# ECC_AGGR6_ECC_AGGR register map
Vendor: Texas Instruments
Registers are 32-bit, access not given, reset 0x0 unless marked. A register's access mark holds for its fields unless they carry their own. Offsets are as the file gives them; [hi:lo] are bit positions.

## ECC_AGGR6_ECC_AGGR (part 4 of 4)
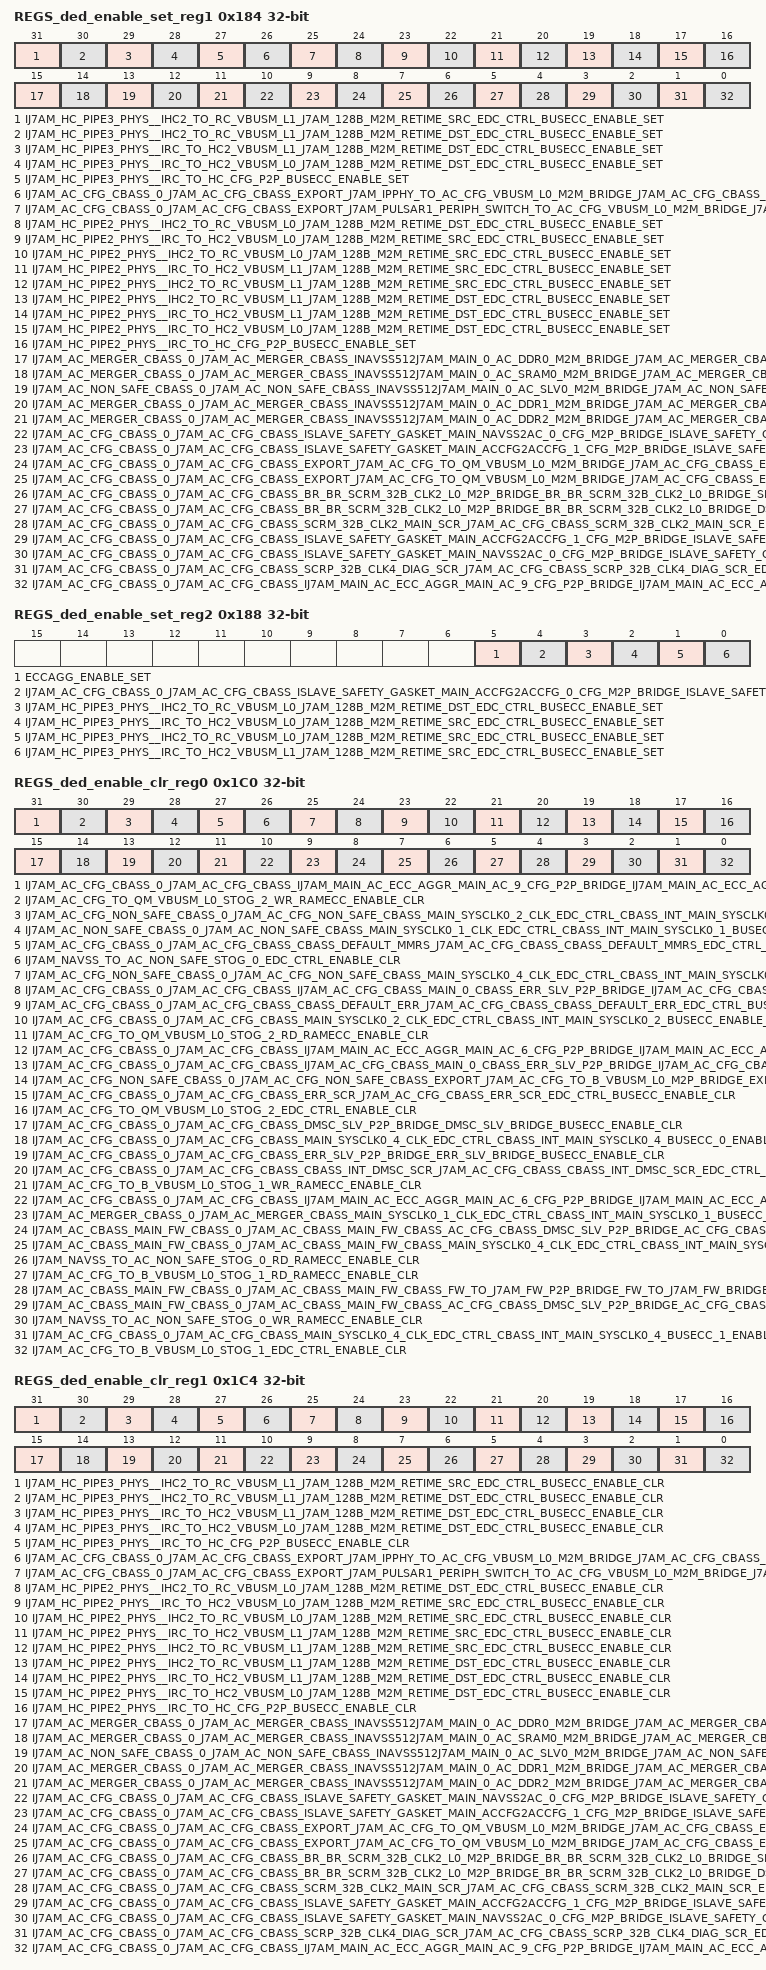
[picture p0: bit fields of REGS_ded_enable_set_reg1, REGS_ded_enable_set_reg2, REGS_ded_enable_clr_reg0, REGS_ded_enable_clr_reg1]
0x184 REGS_ded_enable_set_reg1 — Interrupt Enable Set Register 1
  [31] IJ7AM_HC_PIPE3_PHYS__IHC2_TO_RC_VBUSM_L1_J7AM_128B_M2M_RETIME_SRC_EDC_CTRL_BUSECC_ENABLE_SET — Interrupt Enable Set Register for Ij7am_hc_pipe3_phys__Ihc2_to_rc_vbusm_l1_j7am_128b_m2m_retime_src_edc_ctrl_busecc_pend (access R/W1TS)
  [30] IJ7AM_HC_PIPE3_PHYS__IHC2_TO_RC_VBUSM_L1_J7AM_128B_M2M_RETIME_DST_EDC_CTRL_BUSECC_ENABLE_SET — Interrupt Enable Set Register for Ij7am_hc_pipe3_phys__Ihc2_to_rc_vbusm_l1_j7am_128b_m2m_retime_dst_edc_ctrl_busecc_pend (access R/W1TS)
  [29] IJ7AM_HC_PIPE3_PHYS__IRC_TO_HC2_VBUSM_L1_J7AM_128B_M2M_RETIME_DST_EDC_CTRL_BUSECC_ENABLE_SET — Interrupt Enable Set Register for Ij7am_hc_pipe3_phys__Irc_to_hc2_vbusm_l1_j7am_128b_m2m_retime_dst_edc_ctrl_busecc_pend (access R/W1TS)
  [28] IJ7AM_HC_PIPE3_PHYS__IRC_TO_HC2_VBUSM_L0_J7AM_128B_M2M_RETIME_DST_EDC_CTRL_BUSECC_ENABLE_SET — Interrupt Enable Set Register for Ij7am_hc_pipe3_phys__Irc_to_hc2_vbusm_l0_j7am_128b_m2m_retime_dst_edc_ctrl_busecc_pend (access R/W1TS)
  [27] IJ7AM_HC_PIPE3_PHYS__IRC_TO_HC_CFG_P2P_BUSECC_ENABLE_SET — Interrupt Enable Set Register for Ij7am_hc_pipe3_phys__Irc_to_hc_cfg_p2p_busecc_pend (access R/W1TS)
  [26] IJ7AM_AC_CFG_CBASS_0_J7AM_AC_CFG_CBASS_EXPORT_J7AM_IPPHY_TO_AC_CFG_VBUSM_L0_M2M_BRIDGE_J7AM_AC_CFG_CBASS_EXPORT_J7AM_IPPHY_TO_AC_CFG_VBUSM_L0_M2M_BRIDGE_SRC_EDC_CTRL_BUSECC_ENABLE_SET — Interrupt Enable Set Register for Ij7am_ac_cfg_cbass_0_j7am_ac_cfg_cbass_export_j7am_ipphy_to_ac_cfg_vbusm_l0_m2m_bridge_j7am_ac_cfg_cbass_export_j7am_ipphy_to_ac_cfg_vbusm_l0_m2m_bridge_src_edc_ctrl_busecc_pend (access R/W1TS)
  [25] IJ7AM_AC_CFG_CBASS_0_J7AM_AC_CFG_CBASS_EXPORT_J7AM_PULSAR1_PERIPH_SWITCH_TO_AC_CFG_VBUSM_L0_M2M_BRIDGE_J7AM_AC_CFG_CBASS_EXPORT_J7AM_PULSAR1_PERIPH_SWITCH_TO_AC_CFG_VBUSM_L0_M2M_BRIDGE_SRC_EDC_CTRL_BUSECC_ENABLE_SET — Interrupt Enable Set Register for Ij7am_ac_cfg_cbass_0_j7am_ac_cfg_cbass_export_j7am_pulsar1_periph_switch_to_ac_cfg_vbusm_l0_m2m_bridge_j7am_ac_cfg_cbass_export_j7am_pulsar1_periph_switch_to_ac_cfg_vbusm_l0_m2m_bridge_src_edc_ctrl_busecc_pend (access R/W1TS)
  [24] IJ7AM_HC_PIPE2_PHYS__IHC2_TO_RC_VBUSM_L0_J7AM_128B_M2M_RETIME_DST_EDC_CTRL_BUSECC_ENABLE_SET — Interrupt Enable Set Register for Ij7am_hc_pipe2_phys__Ihc2_to_rc_vbusm_l0_j7am_128b_m2m_retime_dst_edc_ctrl_busecc_pend (access R/W1TS)
  [23] IJ7AM_HC_PIPE2_PHYS__IRC_TO_HC2_VBUSM_L0_J7AM_128B_M2M_RETIME_SRC_EDC_CTRL_BUSECC_ENABLE_SET — Interrupt Enable Set Register for Ij7am_hc_pipe2_phys__Irc_to_hc2_vbusm_l0_j7am_128b_m2m_retime_src_edc_ctrl_busecc_pend (access R/W1TS)
  [22] IJ7AM_HC_PIPE2_PHYS__IHC2_TO_RC_VBUSM_L0_J7AM_128B_M2M_RETIME_SRC_EDC_CTRL_BUSECC_ENABLE_SET — Interrupt Enable Set Register for Ij7am_hc_pipe2_phys__Ihc2_to_rc_vbusm_l0_j7am_128b_m2m_retime_src_edc_ctrl_busecc_pend (access R/W1TS)
  [21] IJ7AM_HC_PIPE2_PHYS__IRC_TO_HC2_VBUSM_L1_J7AM_128B_M2M_RETIME_SRC_EDC_CTRL_BUSECC_ENABLE_SET — Interrupt Enable Set Register for Ij7am_hc_pipe2_phys__Irc_to_hc2_vbusm_l1_j7am_128b_m2m_retime_src_edc_ctrl_busecc_pend (access R/W1TS)
  [20] IJ7AM_HC_PIPE2_PHYS__IHC2_TO_RC_VBUSM_L1_J7AM_128B_M2M_RETIME_SRC_EDC_CTRL_BUSECC_ENABLE_SET — Interrupt Enable Set Register for Ij7am_hc_pipe2_phys__Ihc2_to_rc_vbusm_l1_j7am_128b_m2m_retime_src_edc_ctrl_busecc_pend (access R/W1TS)
  [19] IJ7AM_HC_PIPE2_PHYS__IHC2_TO_RC_VBUSM_L1_J7AM_128B_M2M_RETIME_DST_EDC_CTRL_BUSECC_ENABLE_SET — Interrupt Enable Set Register for Ij7am_hc_pipe2_phys__Ihc2_to_rc_vbusm_l1_j7am_128b_m2m_retime_dst_edc_ctrl_busecc_pend (access R/W1TS)
  [18] IJ7AM_HC_PIPE2_PHYS__IRC_TO_HC2_VBUSM_L1_J7AM_128B_M2M_RETIME_DST_EDC_CTRL_BUSECC_ENABLE_SET — Interrupt Enable Set Register for Ij7am_hc_pipe2_phys__Irc_to_hc2_vbusm_l1_j7am_128b_m2m_retime_dst_edc_ctrl_busecc_pend (access R/W1TS)
  [17] IJ7AM_HC_PIPE2_PHYS__IRC_TO_HC2_VBUSM_L0_J7AM_128B_M2M_RETIME_DST_EDC_CTRL_BUSECC_ENABLE_SET — Interrupt Enable Set Register for Ij7am_hc_pipe2_phys__Irc_to_hc2_vbusm_l0_j7am_128b_m2m_retime_dst_edc_ctrl_busecc_pend (access R/W1TS)
  [16] IJ7AM_HC_PIPE2_PHYS__IRC_TO_HC_CFG_P2P_BUSECC_ENABLE_SET — Interrupt Enable Set Register for Ij7am_hc_pipe2_phys__Irc_to_hc_cfg_p2p_busecc_pend (access R/W1TS)
  [15] IJ7AM_AC_MERGER_CBASS_0_J7AM_AC_MERGER_CBASS_INAVSS512J7AM_MAIN_0_AC_DDR0_M2M_BRIDGE_J7AM_AC_MERGER_CBASS_INAVSS512J7AM_MAIN_0_AC_DDR0_M2M_BRIDGE_SRC_EDC_CTRL_BUSECC_ENABLE_SET — Interrupt Enable Set Register for Ij7am_ac_merger_cbass_0_j7am_ac_merger_cbass_Inavss512j7am_main_0_ac_ddr0_m2m_bridge_j7am_ac_merger_cbass_Inavss512j7am_main_0_ac_ddr0_m2m_bridge_src_edc_ctrl_busecc_pend (access R/W1TS)
  [14] IJ7AM_AC_MERGER_CBASS_0_J7AM_AC_MERGER_CBASS_INAVSS512J7AM_MAIN_0_AC_SRAM0_M2M_BRIDGE_J7AM_AC_MERGER_CBASS_INAVSS512J7AM_MAIN_0_AC_SRAM0_M2M_BRIDGE_SRC_EDC_CTRL_BUSECC_ENABLE_SET — Interrupt Enable Set Register for Ij7am_ac_merger_cbass_0_j7am_ac_merger_cbass_Inavss512j7am_main_0_ac_sram0_m2m_bridge_j7am_ac_merger_cbass_Inavss512j7am_main_0_ac_sram0_m2m_bridge_src_edc_ctrl_busecc_pend (access R/W1TS)
  [13] IJ7AM_AC_NON_SAFE_CBASS_0_J7AM_AC_NON_SAFE_CBASS_INAVSS512J7AM_MAIN_0_AC_SLV0_M2M_BRIDGE_J7AM_AC_NON_SAFE_CBASS_INAVSS512J7AM_MAIN_0_AC_SLV0_M2M_BRIDGE_SRC_EDC_CTRL_BUSECC_ENABLE_SET — Interrupt Enable Set Register for Ij7am_ac_non_safe_cbass_0_j7am_ac_non_safe_cbass_Inavss512j7am_main_0_ac_slv0_m2m_bridge_j7am_ac_non_safe_cbass_Inavss512j7am_main_0_ac_slv0_m2m_bridge_src_edc_ctrl_busecc_pend (access R/W1TS)
  [12] IJ7AM_AC_MERGER_CBASS_0_J7AM_AC_MERGER_CBASS_INAVSS512J7AM_MAIN_0_AC_DDR1_M2M_BRIDGE_J7AM_AC_MERGER_CBASS_INAVSS512J7AM_MAIN_0_AC_DDR1_M2M_BRIDGE_SRC_EDC_CTRL_BUSECC_ENABLE_SET — Interrupt Enable Set Register for Ij7am_ac_merger_cbass_0_j7am_ac_merger_cbass_Inavss512j7am_main_0_ac_ddr1_m2m_bridge_j7am_ac_merger_cbass_Inavss512j7am_main_0_ac_ddr1_m2m_bridge_src_edc_ctrl_busecc_pend (access R/W1TS)
  [11] IJ7AM_AC_MERGER_CBASS_0_J7AM_AC_MERGER_CBASS_INAVSS512J7AM_MAIN_0_AC_DDR2_M2M_BRIDGE_J7AM_AC_MERGER_CBASS_INAVSS512J7AM_MAIN_0_AC_DDR2_M2M_BRIDGE_SRC_EDC_CTRL_BUSECC_ENABLE_SET — Interrupt Enable Set Register for Ij7am_ac_merger_cbass_0_j7am_ac_merger_cbass_Inavss512j7am_main_0_ac_ddr2_m2m_bridge_j7am_ac_merger_cbass_Inavss512j7am_main_0_ac_ddr2_m2m_bridge_src_edc_ctrl_busecc_pend (access R/W1TS)
  [10] IJ7AM_AC_CFG_CBASS_0_J7AM_AC_CFG_CBASS_ISLAVE_SAFETY_GASKET_MAIN_NAVSS2AC_0_CFG_M2P_BRIDGE_ISLAVE_SAFETY_GASKET_MAIN_NAVSS2AC_0_CFG_BRIDGE_DST_BUSECC_ENABLE_SET — Interrupt Enable Set Register for Ij7am_ac_cfg_cbass_0_j7am_ac_cfg_cbass_Islave_safety_gasket_main_navss2ac_0_cfg_m2p_bridge_Islave_safety_gasket_main_navss2ac_0_cfg_bridge_dst_busecc_pend (access R/W1TS)
  [9] IJ7AM_AC_CFG_CBASS_0_J7AM_AC_CFG_CBASS_ISLAVE_SAFETY_GASKET_MAIN_ACCFG2ACCFG_1_CFG_M2P_BRIDGE_ISLAVE_SAFETY_GASKET_MAIN_ACCFG2ACCFG_1_CFG_BRIDGE_DST_BUSECC_ENABLE_SET — Interrupt Enable Set Register for Ij7am_ac_cfg_cbass_0_j7am_ac_cfg_cbass_Islave_safety_gasket_main_accfg2accfg_1_cfg_m2p_bridge_Islave_safety_gasket_main_accfg2accfg_1_cfg_bridge_dst_busecc_pend (access R/W1TS)
  [8] IJ7AM_AC_CFG_CBASS_0_J7AM_AC_CFG_CBASS_EXPORT_J7AM_AC_CFG_TO_QM_VBUSM_L0_M2M_BRIDGE_J7AM_AC_CFG_CBASS_EXPORT_J7AM_AC_CFG_TO_QM_VBUSM_L0_M2M_BRIDGE_DST_EDC_CTRL_BUSECC_ENABLE_SET — Interrupt Enable Set Register for Ij7am_ac_cfg_cbass_0_j7am_ac_cfg_cbass_export_j7am_ac_cfg_to_qm_vbusm_l0_m2m_bridge_j7am_ac_cfg_cbass_export_j7am_ac_cfg_to_qm_vbusm_l0_m2m_bridge_dst_edc_ctrl_busecc_pend (access R/W1TS)
  [7] IJ7AM_AC_CFG_CBASS_0_J7AM_AC_CFG_CBASS_EXPORT_J7AM_AC_CFG_TO_QM_VBUSM_L0_M2M_BRIDGE_J7AM_AC_CFG_CBASS_EXPORT_J7AM_AC_CFG_TO_QM_VBUSM_L0_M2M_BRIDGE_SRC_EDC_CTRL_BUSECC_ENABLE_SET — Interrupt Enable Set Register for Ij7am_ac_cfg_cbass_0_j7am_ac_cfg_cbass_export_j7am_ac_cfg_to_qm_vbusm_l0_m2m_bridge_j7am_ac_cfg_cbass_export_j7am_ac_cfg_to_qm_vbusm_l0_m2m_bridge_src_edc_ctrl_busecc_pend (access R/W1TS)
  [6] IJ7AM_AC_CFG_CBASS_0_J7AM_AC_CFG_CBASS_BR_BR_SCRM_32B_CLK2_L0_M2P_BRIDGE_BR_BR_SCRM_32B_CLK2_L0_BRIDGE_SRC_BUSECC_ENABLE_SET — Interrupt Enable Set Register for Ij7am_ac_cfg_cbass_0_j7am_ac_cfg_cbass_br_br_scrm_32b_clk2_l0_m2p_bridge_br_br_scrm_32b_clk2_l0_bridge_src_busecc_pend (access R/W1TS)
  [5] IJ7AM_AC_CFG_CBASS_0_J7AM_AC_CFG_CBASS_BR_BR_SCRM_32B_CLK2_L0_M2P_BRIDGE_BR_BR_SCRM_32B_CLK2_L0_BRIDGE_DST_BUSECC_ENABLE_SET — Interrupt Enable Set Register for Ij7am_ac_cfg_cbass_0_j7am_ac_cfg_cbass_br_br_scrm_32b_clk2_l0_m2p_bridge_br_br_scrm_32b_clk2_l0_bridge_dst_busecc_pend (access R/W1TS)
  [4] IJ7AM_AC_CFG_CBASS_0_J7AM_AC_CFG_CBASS_SCRM_32B_CLK2_MAIN_SCR_J7AM_AC_CFG_CBASS_SCRM_32B_CLK2_MAIN_SCR_EDC_CTRL_BUSECC_ENABLE_SET — Interrupt Enable Set Register for Ij7am_ac_cfg_cbass_0_j7am_ac_cfg_cbass_scrm_32b_clk2_main_scr_j7am_ac_cfg_cbass_scrm_32b_clk2_main_scr_edc_ctrl_busecc_pend (access R/W1TS)
  [3] IJ7AM_AC_CFG_CBASS_0_J7AM_AC_CFG_CBASS_ISLAVE_SAFETY_GASKET_MAIN_ACCFG2ACCFG_1_CFG_M2P_BRIDGE_ISLAVE_SAFETY_GASKET_MAIN_ACCFG2ACCFG_1_CFG_BRIDGE_SRC_BUSECC_ENABLE_SET — Interrupt Enable Set Register for Ij7am_ac_cfg_cbass_0_j7am_ac_cfg_cbass_Islave_safety_gasket_main_accfg2accfg_1_cfg_m2p_bridge_Islave_safety_gasket_main_accfg2accfg_1_cfg_bridge_src_busecc_pend (access R/W1TS)
  [2] IJ7AM_AC_CFG_CBASS_0_J7AM_AC_CFG_CBASS_ISLAVE_SAFETY_GASKET_MAIN_NAVSS2AC_0_CFG_M2P_BRIDGE_ISLAVE_SAFETY_GASKET_MAIN_NAVSS2AC_0_CFG_BRIDGE_SRC_BUSECC_ENABLE_SET — Interrupt Enable Set Register for Ij7am_ac_cfg_cbass_0_j7am_ac_cfg_cbass_Islave_safety_gasket_main_navss2ac_0_cfg_m2p_bridge_Islave_safety_gasket_main_navss2ac_0_cfg_bridge_src_busecc_pend (access R/W1TS)
  [1] IJ7AM_AC_CFG_CBASS_0_J7AM_AC_CFG_CBASS_SCRP_32B_CLK4_DIAG_SCR_J7AM_AC_CFG_CBASS_SCRP_32B_CLK4_DIAG_SCR_EDC_CTRL_BUSECC_ENABLE_SET — Interrupt Enable Set Register for Ij7am_ac_cfg_cbass_0_j7am_ac_cfg_cbass_scrp_32b_clk4_diag_scr_j7am_ac_cfg_cbass_scrp_32b_clk4_diag_scr_edc_ctrl_busecc_pend (access R/W1TS)
  [0] IJ7AM_AC_CFG_CBASS_0_J7AM_AC_CFG_CBASS_IJ7AM_MAIN_AC_ECC_AGGR_MAIN_AC_9_CFG_P2P_BRIDGE_IJ7AM_MAIN_AC_ECC_AGGR_MAIN_AC_9_CFG_BRIDGE_DST_BUSECC_ENABLE_SET — Interrupt Enable Set Register for Ij7am_ac_cfg_cbass_0_j7am_ac_cfg_cbass_Ij7am_main_ac_ecc_aggr_main_ac_9_cfg_p2p_bridge_Ij7am_main_ac_ecc_aggr_main_ac_9_cfg_bridge_dst_busecc_pend (access R/W1TS)
0x188 REGS_ded_enable_set_reg2 — Interrupt Enable Set Register 2
  [5] ECCAGG_ENABLE_SET — Interrupt Enable Set Register for eccagg_pend (access R/W1TS)
  [4] IJ7AM_AC_CFG_CBASS_0_J7AM_AC_CFG_CBASS_ISLAVE_SAFETY_GASKET_MAIN_ACCFG2ACCFG_0_CFG_M2P_BRIDGE_ISLAVE_SAFETY_GASKET_MAIN_ACCFG2ACCFG_0_CFG_BRIDGE_BUSECC_ENABLE_SET — Interrupt Enable Set Register for Ij7am_ac_cfg_cbass_0_j7am_ac_cfg_cbass_Islave_safety_gasket_main_accfg2accfg_0_cfg_m2p_bridge_Islave_safety_gasket_main_accfg2accfg_0_cfg_bridge_busecc_pend (access R/W1TS)
  [3] IJ7AM_HC_PIPE3_PHYS__IHC2_TO_RC_VBUSM_L0_J7AM_128B_M2M_RETIME_DST_EDC_CTRL_BUSECC_ENABLE_SET — Interrupt Enable Set Register for Ij7am_hc_pipe3_phys__Ihc2_to_rc_vbusm_l0_j7am_128b_m2m_retime_dst_edc_ctrl_busecc_pend (access R/W1TS)
  [2] IJ7AM_HC_PIPE3_PHYS__IRC_TO_HC2_VBUSM_L0_J7AM_128B_M2M_RETIME_SRC_EDC_CTRL_BUSECC_ENABLE_SET — Interrupt Enable Set Register for Ij7am_hc_pipe3_phys__Irc_to_hc2_vbusm_l0_j7am_128b_m2m_retime_src_edc_ctrl_busecc_pend (access R/W1TS)
  [1] IJ7AM_HC_PIPE3_PHYS__IHC2_TO_RC_VBUSM_L0_J7AM_128B_M2M_RETIME_SRC_EDC_CTRL_BUSECC_ENABLE_SET — Interrupt Enable Set Register for Ij7am_hc_pipe3_phys__Ihc2_to_rc_vbusm_l0_j7am_128b_m2m_retime_src_edc_ctrl_busecc_pend (access R/W1TS)
  [0] IJ7AM_HC_PIPE3_PHYS__IRC_TO_HC2_VBUSM_L1_J7AM_128B_M2M_RETIME_SRC_EDC_CTRL_BUSECC_ENABLE_SET — Interrupt Enable Set Register for Ij7am_hc_pipe3_phys__Irc_to_hc2_vbusm_l1_j7am_128b_m2m_retime_src_edc_ctrl_busecc_pend (access R/W1TS)
0x1C0 REGS_ded_enable_clr_reg0 — Interrupt Enable Clear Register 0
  [31] IJ7AM_AC_CFG_CBASS_0_J7AM_AC_CFG_CBASS_IJ7AM_MAIN_AC_ECC_AGGR_MAIN_AC_9_CFG_P2P_BRIDGE_IJ7AM_MAIN_AC_ECC_AGGR_MAIN_AC_9_CFG_BRIDGE_SRC_BUSECC_ENABLE_CLR — Interrupt Enable Clear Register for Ij7am_ac_cfg_cbass_0_j7am_ac_cfg_cbass_Ij7am_main_ac_ecc_aggr_main_ac_9_cfg_p2p_bridge_Ij7am_main_ac_ecc_aggr_main_ac_9_cfg_bridge_src_busecc_pend (access R/W1TC)
  [30] IJ7AM_AC_CFG_TO_QM_VBUSM_L0_STOG_2_WR_RAMECC_ENABLE_CLR — Interrupt Enable Clear Register for Ij7am_ac_cfg_to_qm_vbusm_l0_stog_2_wr_ramecc_pend (access R/W1TC)
  [29] IJ7AM_AC_CFG_NON_SAFE_CBASS_0_J7AM_AC_CFG_NON_SAFE_CBASS_MAIN_SYSCLK0_2_CLK_EDC_CTRL_CBASS_INT_MAIN_SYSCLK0_2_BUSECC_ENABLE_CLR — Interrupt Enable Clear Register for Ij7am_ac_cfg_non_safe_cbass_0_j7am_ac_cfg_non_safe_cbass_main_SYSCLK0_2_clk_edc_ctrl_cbass_int_main_SYSCLK0_2_busecc_pend (access R/W1TC)
  [28] IJ7AM_AC_NON_SAFE_CBASS_0_J7AM_AC_NON_SAFE_CBASS_MAIN_SYSCLK0_1_CLK_EDC_CTRL_CBASS_INT_MAIN_SYSCLK0_1_BUSECC_ENABLE_CLR — Interrupt Enable Clear Register for Ij7am_ac_non_safe_cbass_0_j7am_ac_non_safe_cbass_main_SYSCLK0_1_clk_edc_ctrl_cbass_int_main_SYSCLK0_1_busecc_pend (access R/W1TC)
  [27] IJ7AM_AC_CFG_CBASS_0_J7AM_AC_CFG_CBASS_CBASS_DEFAULT_MMRS_J7AM_AC_CFG_CBASS_CBASS_DEFAULT_MMRS_EDC_CTRL_BUSECC_ENABLE_CLR — Interrupt Enable Clear Register for Ij7am_ac_cfg_cbass_0_j7am_ac_cfg_cbass_cbass_default_mmrs_j7am_ac_cfg_cbass_cbass_default_mmrs_edc_ctrl_busecc_pend (access R/W1TC)
  [26] IJ7AM_NAVSS_TO_AC_NON_SAFE_STOG_0_EDC_CTRL_ENABLE_CLR — Interrupt Enable Clear Register for Ij7am_navss_to_ac_non_safe_stog_0_edc_ctrl_pend (access R/W1TC)
  [25] IJ7AM_AC_CFG_NON_SAFE_CBASS_0_J7AM_AC_CFG_NON_SAFE_CBASS_MAIN_SYSCLK0_4_CLK_EDC_CTRL_CBASS_INT_MAIN_SYSCLK0_4_BUSECC_ENABLE_CLR — Interrupt Enable Clear Register for Ij7am_ac_cfg_non_safe_cbass_0_j7am_ac_cfg_non_safe_cbass_main_SYSCLK0_4_clk_edc_ctrl_cbass_int_main_SYSCLK0_4_busecc_pend (access R/W1TC)
  [24] IJ7AM_AC_CFG_CBASS_0_J7AM_AC_CFG_CBASS_IJ7AM_AC_CFG_CBASS_MAIN_0_CBASS_ERR_SLV_P2P_BRIDGE_IJ7AM_AC_CFG_CBASS_MAIN_0_CBASS_ERR_SLV_BRIDGE_SRC_BUSECC_ENABLE_CLR — Interrupt Enable Clear Register for Ij7am_ac_cfg_cbass_0_j7am_ac_cfg_cbass_Ij7am_ac_cfg_cbass_main_0_cbass_err_slv_p2p_bridge_Ij7am_ac_cfg_cbass_main_0_cbass_err_slv_bridge_src_busecc_pend (access R/W1TC)
  [23] IJ7AM_AC_CFG_CBASS_0_J7AM_AC_CFG_CBASS_CBASS_DEFAULT_ERR_J7AM_AC_CFG_CBASS_CBASS_DEFAULT_ERR_EDC_CTRL_BUSECC_ENABLE_CLR — Interrupt Enable Clear Register for Ij7am_ac_cfg_cbass_0_j7am_ac_cfg_cbass_cbass_default_err_j7am_ac_cfg_cbass_cbass_default_err_edc_ctrl_busecc_pend (access R/W1TC)
  [22] IJ7AM_AC_CFG_CBASS_0_J7AM_AC_CFG_CBASS_MAIN_SYSCLK0_2_CLK_EDC_CTRL_CBASS_INT_MAIN_SYSCLK0_2_BUSECC_ENABLE_CLR — Interrupt Enable Clear Register for Ij7am_ac_cfg_cbass_0_j7am_ac_cfg_cbass_main_SYSCLK0_2_clk_edc_ctrl_cbass_int_main_SYSCLK0_2_busecc_pend (access R/W1TC)
  [21] IJ7AM_AC_CFG_TO_QM_VBUSM_L0_STOG_2_RD_RAMECC_ENABLE_CLR — Interrupt Enable Clear Register for Ij7am_ac_cfg_to_qm_vbusm_l0_stog_2_rd_ramecc_pend (access R/W1TC)
  [20] IJ7AM_AC_CFG_CBASS_0_J7AM_AC_CFG_CBASS_IJ7AM_MAIN_AC_ECC_AGGR_MAIN_AC_6_CFG_P2P_BRIDGE_IJ7AM_MAIN_AC_ECC_AGGR_MAIN_AC_6_CFG_BRIDGE_SRC_BUSECC_ENABLE_CLR — Interrupt Enable Clear Register for Ij7am_ac_cfg_cbass_0_j7am_ac_cfg_cbass_Ij7am_main_ac_ecc_aggr_main_ac_6_cfg_p2p_bridge_Ij7am_main_ac_ecc_aggr_main_ac_6_cfg_bridge_src_busecc_pend (access R/W1TC)
  [19] IJ7AM_AC_CFG_CBASS_0_J7AM_AC_CFG_CBASS_IJ7AM_AC_CFG_CBASS_MAIN_0_CBASS_ERR_SLV_P2P_BRIDGE_IJ7AM_AC_CFG_CBASS_MAIN_0_CBASS_ERR_SLV_BRIDGE_DST_BUSECC_ENABLE_CLR — Interrupt Enable Clear Register for Ij7am_ac_cfg_cbass_0_j7am_ac_cfg_cbass_Ij7am_ac_cfg_cbass_main_0_cbass_err_slv_p2p_bridge_Ij7am_ac_cfg_cbass_main_0_cbass_err_slv_bridge_dst_busecc_pend (access R/W1TC)
  [18] IJ7AM_AC_CFG_NON_SAFE_CBASS_0_J7AM_AC_CFG_NON_SAFE_CBASS_EXPORT_J7AM_AC_CFG_TO_B_VBUSM_L0_M2P_BRIDGE_EXPORT_J7AM_AC_CFG_TO_B_VBUSM_L0_BRIDGE_BUSECC_ENABLE_CLR — Interrupt Enable Clear Register for Ij7am_ac_cfg_non_safe_cbass_0_j7am_ac_cfg_non_safe_cbass_export_j7am_ac_cfg_to_b_vbusm_l0_m2p_bridge_export_j7am_ac_cfg_to_b_vbusm_l0_bridge_busecc_pend (access R/W1TC)
  [17] IJ7AM_AC_CFG_CBASS_0_J7AM_AC_CFG_CBASS_ERR_SCR_J7AM_AC_CFG_CBASS_ERR_SCR_EDC_CTRL_BUSECC_ENABLE_CLR — Interrupt Enable Clear Register for Ij7am_ac_cfg_cbass_0_j7am_ac_cfg_cbass_err_scr_j7am_ac_cfg_cbass_err_scr_edc_ctrl_busecc_pend (access R/W1TC)
  [16] IJ7AM_AC_CFG_TO_QM_VBUSM_L0_STOG_2_EDC_CTRL_ENABLE_CLR — Interrupt Enable Clear Register for Ij7am_ac_cfg_to_qm_vbusm_l0_stog_2_edc_ctrl_pend (access R/W1TC)
  [15] IJ7AM_AC_CFG_CBASS_0_J7AM_AC_CFG_CBASS_DMSC_SLV_P2P_BRIDGE_DMSC_SLV_BRIDGE_BUSECC_ENABLE_CLR — Interrupt Enable Clear Register for Ij7am_ac_cfg_cbass_0_j7am_ac_cfg_cbass_dmsc_slv_p2p_bridge_dmsc_slv_bridge_busecc_pend (access R/W1TC)
  [14] IJ7AM_AC_CFG_CBASS_0_J7AM_AC_CFG_CBASS_MAIN_SYSCLK0_4_CLK_EDC_CTRL_CBASS_INT_MAIN_SYSCLK0_4_BUSECC_0_ENABLE_CLR — Interrupt Enable Clear Register for Ij7am_ac_cfg_cbass_0_j7am_ac_cfg_cbass_main_SYSCLK0_4_clk_edc_ctrl_cbass_int_main_SYSCLK0_4_busecc_0_pend (access R/W1TC)
  [13] IJ7AM_AC_CFG_CBASS_0_J7AM_AC_CFG_CBASS_ERR_SLV_P2P_BRIDGE_ERR_SLV_BRIDGE_BUSECC_ENABLE_CLR — Interrupt Enable Clear Register for Ij7am_ac_cfg_cbass_0_j7am_ac_cfg_cbass_err_slv_p2p_bridge_err_slv_bridge_busecc_pend (access R/W1TC)
  [12] IJ7AM_AC_CFG_CBASS_0_J7AM_AC_CFG_CBASS_CBASS_INT_DMSC_SCR_J7AM_AC_CFG_CBASS_CBASS_INT_DMSC_SCR_EDC_CTRL_BUSECC_ENABLE_CLR — Interrupt Enable Clear Register for Ij7am_ac_cfg_cbass_0_j7am_ac_cfg_cbass_cbass_int_dmsc_scr_j7am_ac_cfg_cbass_cbass_int_dmsc_scr_edc_ctrl_busecc_pend (access R/W1TC)
  [11] IJ7AM_AC_CFG_TO_B_VBUSM_L0_STOG_1_WR_RAMECC_ENABLE_CLR — Interrupt Enable Clear Register for Ij7am_ac_cfg_to_b_vbusm_l0_stog_1_wr_ramecc_pend (access R/W1TC)
  [10] IJ7AM_AC_CFG_CBASS_0_J7AM_AC_CFG_CBASS_IJ7AM_MAIN_AC_ECC_AGGR_MAIN_AC_6_CFG_P2P_BRIDGE_IJ7AM_MAIN_AC_ECC_AGGR_MAIN_AC_6_CFG_BRIDGE_DST_BUSECC_ENABLE_CLR — Interrupt Enable Clear Register for Ij7am_ac_cfg_cbass_0_j7am_ac_cfg_cbass_Ij7am_main_ac_ecc_aggr_main_ac_6_cfg_p2p_bridge_Ij7am_main_ac_ecc_aggr_main_ac_6_cfg_bridge_dst_busecc_pend (access R/W1TC)
  [9] IJ7AM_AC_MERGER_CBASS_0_J7AM_AC_MERGER_CBASS_MAIN_SYSCLK0_1_CLK_EDC_CTRL_CBASS_INT_MAIN_SYSCLK0_1_BUSECC_ENABLE_CLR — Interrupt Enable Clear Register for Ij7am_ac_merger_cbass_0_j7am_ac_merger_cbass_main_SYSCLK0_1_clk_edc_ctrl_cbass_int_main_SYSCLK0_1_busecc_pend (access R/W1TC)
  [8] IJ7AM_AC_CBASS_MAIN_FW_CBASS_0_J7AM_AC_CBASS_MAIN_FW_CBASS_AC_CFG_CBASS_DMSC_SLV_P2P_BRIDGE_AC_CFG_CBASS_DMSC_SLV_BRIDGE_SRC_BUSECC_ENABLE_CLR — Interrupt Enable Clear Register for Ij7am_ac_cbass_main_fw_cbass_0_j7am_ac_cbass_main_fw_cbass_ac_cfg_cbass_dmsc_slv_p2p_bridge_ac_cfg_cbass_dmsc_slv_bridge_src_busecc_pend (access R/W1TC)
  [7] IJ7AM_AC_CBASS_MAIN_FW_CBASS_0_J7AM_AC_CBASS_MAIN_FW_CBASS_MAIN_SYSCLK0_4_CLK_EDC_CTRL_CBASS_INT_MAIN_SYSCLK0_4_BUSECC_ENABLE_CLR — Interrupt Enable Clear Register for Ij7am_ac_cbass_main_fw_cbass_0_j7am_ac_cbass_main_fw_cbass_main_SYSCLK0_4_clk_edc_ctrl_cbass_int_main_SYSCLK0_4_busecc_pend (access R/W1TC)
  [6] IJ7AM_NAVSS_TO_AC_NON_SAFE_STOG_0_RD_RAMECC_ENABLE_CLR — Interrupt Enable Clear Register for Ij7am_navss_to_ac_non_safe_stog_0_rd_ramecc_pend (access R/W1TC)
  [5] IJ7AM_AC_CFG_TO_B_VBUSM_L0_STOG_1_RD_RAMECC_ENABLE_CLR — Interrupt Enable Clear Register for Ij7am_ac_cfg_to_b_vbusm_l0_stog_1_rd_ramecc_pend (access R/W1TC)
  [4] IJ7AM_AC_CBASS_MAIN_FW_CBASS_0_J7AM_AC_CBASS_MAIN_FW_CBASS_FW_TO_J7AM_FW_P2P_BRIDGE_FW_TO_J7AM_FW_BRIDGE_BUSECC_ENABLE_CLR — Interrupt Enable Clear Register for Ij7am_ac_cbass_main_fw_cbass_0_j7am_ac_cbass_main_fw_cbass_fw_to_j7am_fw_p2p_bridge_fw_to_j7am_fw_bridge_busecc_pend (access R/W1TC)
  [3] IJ7AM_AC_CBASS_MAIN_FW_CBASS_0_J7AM_AC_CBASS_MAIN_FW_CBASS_AC_CFG_CBASS_DMSC_SLV_P2P_BRIDGE_AC_CFG_CBASS_DMSC_SLV_BRIDGE_DST_BUSECC_ENABLE_CLR — Interrupt Enable Clear Register for Ij7am_ac_cbass_main_fw_cbass_0_j7am_ac_cbass_main_fw_cbass_ac_cfg_cbass_dmsc_slv_p2p_bridge_ac_cfg_cbass_dmsc_slv_bridge_dst_busecc_pend (access R/W1TC)
  [2] IJ7AM_NAVSS_TO_AC_NON_SAFE_STOG_0_WR_RAMECC_ENABLE_CLR — Interrupt Enable Clear Register for Ij7am_navss_to_ac_non_safe_stog_0_wr_ramecc_pend (access R/W1TC)
  [1] IJ7AM_AC_CFG_CBASS_0_J7AM_AC_CFG_CBASS_MAIN_SYSCLK0_4_CLK_EDC_CTRL_CBASS_INT_MAIN_SYSCLK0_4_BUSECC_1_ENABLE_CLR — Interrupt Enable Clear Register for Ij7am_ac_cfg_cbass_0_j7am_ac_cfg_cbass_main_SYSCLK0_4_clk_edc_ctrl_cbass_int_main_SYSCLK0_4_busecc_1_pend (access R/W1TC)
  [0] IJ7AM_AC_CFG_TO_B_VBUSM_L0_STOG_1_EDC_CTRL_ENABLE_CLR — Interrupt Enable Clear Register for Ij7am_ac_cfg_to_b_vbusm_l0_stog_1_edc_ctrl_pend (access R/W1TC)
0x1C4 REGS_ded_enable_clr_reg1 — Interrupt Enable Clear Register 1
  [31] IJ7AM_HC_PIPE3_PHYS__IHC2_TO_RC_VBUSM_L1_J7AM_128B_M2M_RETIME_SRC_EDC_CTRL_BUSECC_ENABLE_CLR — Interrupt Enable Clear Register for Ij7am_hc_pipe3_phys__Ihc2_to_rc_vbusm_l1_j7am_128b_m2m_retime_src_edc_ctrl_busecc_pend (access R/W1TC)
  [30] IJ7AM_HC_PIPE3_PHYS__IHC2_TO_RC_VBUSM_L1_J7AM_128B_M2M_RETIME_DST_EDC_CTRL_BUSECC_ENABLE_CLR — Interrupt Enable Clear Register for Ij7am_hc_pipe3_phys__Ihc2_to_rc_vbusm_l1_j7am_128b_m2m_retime_dst_edc_ctrl_busecc_pend (access R/W1TC)
  [29] IJ7AM_HC_PIPE3_PHYS__IRC_TO_HC2_VBUSM_L1_J7AM_128B_M2M_RETIME_DST_EDC_CTRL_BUSECC_ENABLE_CLR — Interrupt Enable Clear Register for Ij7am_hc_pipe3_phys__Irc_to_hc2_vbusm_l1_j7am_128b_m2m_retime_dst_edc_ctrl_busecc_pend (access R/W1TC)
  [28] IJ7AM_HC_PIPE3_PHYS__IRC_TO_HC2_VBUSM_L0_J7AM_128B_M2M_RETIME_DST_EDC_CTRL_BUSECC_ENABLE_CLR — Interrupt Enable Clear Register for Ij7am_hc_pipe3_phys__Irc_to_hc2_vbusm_l0_j7am_128b_m2m_retime_dst_edc_ctrl_busecc_pend (access R/W1TC)
  [27] IJ7AM_HC_PIPE3_PHYS__IRC_TO_HC_CFG_P2P_BUSECC_ENABLE_CLR — Interrupt Enable Clear Register for Ij7am_hc_pipe3_phys__Irc_to_hc_cfg_p2p_busecc_pend (access R/W1TC)
  [26] IJ7AM_AC_CFG_CBASS_0_J7AM_AC_CFG_CBASS_EXPORT_J7AM_IPPHY_TO_AC_CFG_VBUSM_L0_M2M_BRIDGE_J7AM_AC_CFG_CBASS_EXPORT_J7AM_IPPHY_TO_AC_CFG_VBUSM_L0_M2M_BRIDGE_SRC_EDC_CTRL_BUSECC_ENABLE_CLR — Interrupt Enable Clear Register for Ij7am_ac_cfg_cbass_0_j7am_ac_cfg_cbass_export_j7am_ipphy_to_ac_cfg_vbusm_l0_m2m_bridge_j7am_ac_cfg_cbass_export_j7am_ipphy_to_ac_cfg_vbusm_l0_m2m_bridge_src_edc_ctrl_busecc_pend (access R/W1TC)
  [25] IJ7AM_AC_CFG_CBASS_0_J7AM_AC_CFG_CBASS_EXPORT_J7AM_PULSAR1_PERIPH_SWITCH_TO_AC_CFG_VBUSM_L0_M2M_BRIDGE_J7AM_AC_CFG_CBASS_EXPORT_J7AM_PULSAR1_PERIPH_SWITCH_TO_AC_CFG_VBUSM_L0_M2M_BRIDGE_SRC_EDC_CTRL_BUSECC_ENABLE_CLR — Interrupt Enable Clear Register for Ij7am_ac_cfg_cbass_0_j7am_ac_cfg_cbass_export_j7am_pulsar1_periph_switch_to_ac_cfg_vbusm_l0_m2m_bridge_j7am_ac_cfg_cbass_export_j7am_pulsar1_periph_switch_to_ac_cfg_vbusm_l0_m2m_bridge_src_edc_ctrl_busecc_pend (access R/W1TC)
  [24] IJ7AM_HC_PIPE2_PHYS__IHC2_TO_RC_VBUSM_L0_J7AM_128B_M2M_RETIME_DST_EDC_CTRL_BUSECC_ENABLE_CLR — Interrupt Enable Clear Register for Ij7am_hc_pipe2_phys__Ihc2_to_rc_vbusm_l0_j7am_128b_m2m_retime_dst_edc_ctrl_busecc_pend (access R/W1TC)
  [23] IJ7AM_HC_PIPE2_PHYS__IRC_TO_HC2_VBUSM_L0_J7AM_128B_M2M_RETIME_SRC_EDC_CTRL_BUSECC_ENABLE_CLR — Interrupt Enable Clear Register for Ij7am_hc_pipe2_phys__Irc_to_hc2_vbusm_l0_j7am_128b_m2m_retime_src_edc_ctrl_busecc_pend (access R/W1TC)
  [22] IJ7AM_HC_PIPE2_PHYS__IHC2_TO_RC_VBUSM_L0_J7AM_128B_M2M_RETIME_SRC_EDC_CTRL_BUSECC_ENABLE_CLR — Interrupt Enable Clear Register for Ij7am_hc_pipe2_phys__Ihc2_to_rc_vbusm_l0_j7am_128b_m2m_retime_src_edc_ctrl_busecc_pend (access R/W1TC)
  [21] IJ7AM_HC_PIPE2_PHYS__IRC_TO_HC2_VBUSM_L1_J7AM_128B_M2M_RETIME_SRC_EDC_CTRL_BUSECC_ENABLE_CLR — Interrupt Enable Clear Register for Ij7am_hc_pipe2_phys__Irc_to_hc2_vbusm_l1_j7am_128b_m2m_retime_src_edc_ctrl_busecc_pend (access R/W1TC)
  [20] IJ7AM_HC_PIPE2_PHYS__IHC2_TO_RC_VBUSM_L1_J7AM_128B_M2M_RETIME_SRC_EDC_CTRL_BUSECC_ENABLE_CLR — Interrupt Enable Clear Register for Ij7am_hc_pipe2_phys__Ihc2_to_rc_vbusm_l1_j7am_128b_m2m_retime_src_edc_ctrl_busecc_pend (access R/W1TC)
  [19] IJ7AM_HC_PIPE2_PHYS__IHC2_TO_RC_VBUSM_L1_J7AM_128B_M2M_RETIME_DST_EDC_CTRL_BUSECC_ENABLE_CLR — Interrupt Enable Clear Register for Ij7am_hc_pipe2_phys__Ihc2_to_rc_vbusm_l1_j7am_128b_m2m_retime_dst_edc_ctrl_busecc_pend (access R/W1TC)
  [18] IJ7AM_HC_PIPE2_PHYS__IRC_TO_HC2_VBUSM_L1_J7AM_128B_M2M_RETIME_DST_EDC_CTRL_BUSECC_ENABLE_CLR — Interrupt Enable Clear Register for Ij7am_hc_pipe2_phys__Irc_to_hc2_vbusm_l1_j7am_128b_m2m_retime_dst_edc_ctrl_busecc_pend (access R/W1TC)
  [17] IJ7AM_HC_PIPE2_PHYS__IRC_TO_HC2_VBUSM_L0_J7AM_128B_M2M_RETIME_DST_EDC_CTRL_BUSECC_ENABLE_CLR — Interrupt Enable Clear Register for Ij7am_hc_pipe2_phys__Irc_to_hc2_vbusm_l0_j7am_128b_m2m_retime_dst_edc_ctrl_busecc_pend (access R/W1TC)
  [16] IJ7AM_HC_PIPE2_PHYS__IRC_TO_HC_CFG_P2P_BUSECC_ENABLE_CLR — Interrupt Enable Clear Register for Ij7am_hc_pipe2_phys__Irc_to_hc_cfg_p2p_busecc_pend (access R/W1TC)
  [15] IJ7AM_AC_MERGER_CBASS_0_J7AM_AC_MERGER_CBASS_INAVSS512J7AM_MAIN_0_AC_DDR0_M2M_BRIDGE_J7AM_AC_MERGER_CBASS_INAVSS512J7AM_MAIN_0_AC_DDR0_M2M_BRIDGE_SRC_EDC_CTRL_BUSECC_ENABLE_CLR — Interrupt Enable Clear Register for Ij7am_ac_merger_cbass_0_j7am_ac_merger_cbass_Inavss512j7am_main_0_ac_ddr0_m2m_bridge_j7am_ac_merger_cbass_Inavss512j7am_main_0_ac_ddr0_m2m_bridge_src_edc_ctrl_busecc_pend (access R/W1TC)
  [14] IJ7AM_AC_MERGER_CBASS_0_J7AM_AC_MERGER_CBASS_INAVSS512J7AM_MAIN_0_AC_SRAM0_M2M_BRIDGE_J7AM_AC_MERGER_CBASS_INAVSS512J7AM_MAIN_0_AC_SRAM0_M2M_BRIDGE_SRC_EDC_CTRL_BUSECC_ENABLE_CLR — Interrupt Enable Clear Register for Ij7am_ac_merger_cbass_0_j7am_ac_merger_cbass_Inavss512j7am_main_0_ac_sram0_m2m_bridge_j7am_ac_merger_cbass_Inavss512j7am_main_0_ac_sram0_m2m_bridge_src_edc_ctrl_busecc_pend (access R/W1TC)
  [13] IJ7AM_AC_NON_SAFE_CBASS_0_J7AM_AC_NON_SAFE_CBASS_INAVSS512J7AM_MAIN_0_AC_SLV0_M2M_BRIDGE_J7AM_AC_NON_SAFE_CBASS_INAVSS512J7AM_MAIN_0_AC_SLV0_M2M_BRIDGE_SRC_EDC_CTRL_BUSECC_ENABLE_CLR — Interrupt Enable Clear Register for Ij7am_ac_non_safe_cbass_0_j7am_ac_non_safe_cbass_Inavss512j7am_main_0_ac_slv0_m2m_bridge_j7am_ac_non_safe_cbass_Inavss512j7am_main_0_ac_slv0_m2m_bridge_src_edc_ctrl_busecc_pend (access R/W1TC)
  [12] IJ7AM_AC_MERGER_CBASS_0_J7AM_AC_MERGER_CBASS_INAVSS512J7AM_MAIN_0_AC_DDR1_M2M_BRIDGE_J7AM_AC_MERGER_CBASS_INAVSS512J7AM_MAIN_0_AC_DDR1_M2M_BRIDGE_SRC_EDC_CTRL_BUSECC_ENABLE_CLR — Interrupt Enable Clear Register for Ij7am_ac_merger_cbass_0_j7am_ac_merger_cbass_Inavss512j7am_main_0_ac_ddr1_m2m_bridge_j7am_ac_merger_cbass_Inavss512j7am_main_0_ac_ddr1_m2m_bridge_src_edc_ctrl_busecc_pend (access R/W1TC)
  [11] IJ7AM_AC_MERGER_CBASS_0_J7AM_AC_MERGER_CBASS_INAVSS512J7AM_MAIN_0_AC_DDR2_M2M_BRIDGE_J7AM_AC_MERGER_CBASS_INAVSS512J7AM_MAIN_0_AC_DDR2_M2M_BRIDGE_SRC_EDC_CTRL_BUSECC_ENABLE_CLR — Interrupt Enable Clear Register for Ij7am_ac_merger_cbass_0_j7am_ac_merger_cbass_Inavss512j7am_main_0_ac_ddr2_m2m_bridge_j7am_ac_merger_cbass_Inavss512j7am_main_0_ac_ddr2_m2m_bridge_src_edc_ctrl_busecc_pend (access R/W1TC)
  [10] IJ7AM_AC_CFG_CBASS_0_J7AM_AC_CFG_CBASS_ISLAVE_SAFETY_GASKET_MAIN_NAVSS2AC_0_CFG_M2P_BRIDGE_ISLAVE_SAFETY_GASKET_MAIN_NAVSS2AC_0_CFG_BRIDGE_DST_BUSECC_ENABLE_CLR — Interrupt Enable Clear Register for Ij7am_ac_cfg_cbass_0_j7am_ac_cfg_cbass_Islave_safety_gasket_main_navss2ac_0_cfg_m2p_bridge_Islave_safety_gasket_main_navss2ac_0_cfg_bridge_dst_busecc_pend (access R/W1TC)
  [9] IJ7AM_AC_CFG_CBASS_0_J7AM_AC_CFG_CBASS_ISLAVE_SAFETY_GASKET_MAIN_ACCFG2ACCFG_1_CFG_M2P_BRIDGE_ISLAVE_SAFETY_GASKET_MAIN_ACCFG2ACCFG_1_CFG_BRIDGE_DST_BUSECC_ENABLE_CLR — Interrupt Enable Clear Register for Ij7am_ac_cfg_cbass_0_j7am_ac_cfg_cbass_Islave_safety_gasket_main_accfg2accfg_1_cfg_m2p_bridge_Islave_safety_gasket_main_accfg2accfg_1_cfg_bridge_dst_busecc_pend (access R/W1TC)
  [8] IJ7AM_AC_CFG_CBASS_0_J7AM_AC_CFG_CBASS_EXPORT_J7AM_AC_CFG_TO_QM_VBUSM_L0_M2M_BRIDGE_J7AM_AC_CFG_CBASS_EXPORT_J7AM_AC_CFG_TO_QM_VBUSM_L0_M2M_BRIDGE_DST_EDC_CTRL_BUSECC_ENABLE_CLR — Interrupt Enable Clear Register for Ij7am_ac_cfg_cbass_0_j7am_ac_cfg_cbass_export_j7am_ac_cfg_to_qm_vbusm_l0_m2m_bridge_j7am_ac_cfg_cbass_export_j7am_ac_cfg_to_qm_vbusm_l0_m2m_bridge_dst_edc_ctrl_busecc_pend (access R/W1TC)
  [7] IJ7AM_AC_CFG_CBASS_0_J7AM_AC_CFG_CBASS_EXPORT_J7AM_AC_CFG_TO_QM_VBUSM_L0_M2M_BRIDGE_J7AM_AC_CFG_CBASS_EXPORT_J7AM_AC_CFG_TO_QM_VBUSM_L0_M2M_BRIDGE_SRC_EDC_CTRL_BUSECC_ENABLE_CLR — Interrupt Enable Clear Register for Ij7am_ac_cfg_cbass_0_j7am_ac_cfg_cbass_export_j7am_ac_cfg_to_qm_vbusm_l0_m2m_bridge_j7am_ac_cfg_cbass_export_j7am_ac_cfg_to_qm_vbusm_l0_m2m_bridge_src_edc_ctrl_busecc_pend (access R/W1TC)
  [6] IJ7AM_AC_CFG_CBASS_0_J7AM_AC_CFG_CBASS_BR_BR_SCRM_32B_CLK2_L0_M2P_BRIDGE_BR_BR_SCRM_32B_CLK2_L0_BRIDGE_SRC_BUSECC_ENABLE_CLR — Interrupt Enable Clear Register for Ij7am_ac_cfg_cbass_0_j7am_ac_cfg_cbass_br_br_scrm_32b_clk2_l0_m2p_bridge_br_br_scrm_32b_clk2_l0_bridge_src_busecc_pend (access R/W1TC)
  [5] IJ7AM_AC_CFG_CBASS_0_J7AM_AC_CFG_CBASS_BR_BR_SCRM_32B_CLK2_L0_M2P_BRIDGE_BR_BR_SCRM_32B_CLK2_L0_BRIDGE_DST_BUSECC_ENABLE_CLR — Interrupt Enable Clear Register for Ij7am_ac_cfg_cbass_0_j7am_ac_cfg_cbass_br_br_scrm_32b_clk2_l0_m2p_bridge_br_br_scrm_32b_clk2_l0_bridge_dst_busecc_pend (access R/W1TC)
  [4] IJ7AM_AC_CFG_CBASS_0_J7AM_AC_CFG_CBASS_SCRM_32B_CLK2_MAIN_SCR_J7AM_AC_CFG_CBASS_SCRM_32B_CLK2_MAIN_SCR_EDC_CTRL_BUSECC_ENABLE_CLR — Interrupt Enable Clear Register for Ij7am_ac_cfg_cbass_0_j7am_ac_cfg_cbass_scrm_32b_clk2_main_scr_j7am_ac_cfg_cbass_scrm_32b_clk2_main_scr_edc_ctrl_busecc_pend (access R/W1TC)
  [3] IJ7AM_AC_CFG_CBASS_0_J7AM_AC_CFG_CBASS_ISLAVE_SAFETY_GASKET_MAIN_ACCFG2ACCFG_1_CFG_M2P_BRIDGE_ISLAVE_SAFETY_GASKET_MAIN_ACCFG2ACCFG_1_CFG_BRIDGE_SRC_BUSECC_ENABLE_CLR — Interrupt Enable Clear Register for Ij7am_ac_cfg_cbass_0_j7am_ac_cfg_cbass_Islave_safety_gasket_main_accfg2accfg_1_cfg_m2p_bridge_Islave_safety_gasket_main_accfg2accfg_1_cfg_bridge_src_busecc_pend (access R/W1TC)
  [2] IJ7AM_AC_CFG_CBASS_0_J7AM_AC_CFG_CBASS_ISLAVE_SAFETY_GASKET_MAIN_NAVSS2AC_0_CFG_M2P_BRIDGE_ISLAVE_SAFETY_GASKET_MAIN_NAVSS2AC_0_CFG_BRIDGE_SRC_BUSECC_ENABLE_CLR — Interrupt Enable Clear Register for Ij7am_ac_cfg_cbass_0_j7am_ac_cfg_cbass_Islave_safety_gasket_main_navss2ac_0_cfg_m2p_bridge_Islave_safety_gasket_main_navss2ac_0_cfg_bridge_src_busecc_pend (access R/W1TC)
  [1] IJ7AM_AC_CFG_CBASS_0_J7AM_AC_CFG_CBASS_SCRP_32B_CLK4_DIAG_SCR_J7AM_AC_CFG_CBASS_SCRP_32B_CLK4_DIAG_SCR_EDC_CTRL_BUSECC_ENABLE_CLR — Interrupt Enable Clear Register for Ij7am_ac_cfg_cbass_0_j7am_ac_cfg_cbass_scrp_32b_clk4_diag_scr_j7am_ac_cfg_cbass_scrp_32b_clk4_diag_scr_edc_ctrl_busecc_pend (access R/W1TC)
  [0] IJ7AM_AC_CFG_CBASS_0_J7AM_AC_CFG_CBASS_IJ7AM_MAIN_AC_ECC_AGGR_MAIN_AC_9_CFG_P2P_BRIDGE_IJ7AM_MAIN_AC_ECC_AGGR_MAIN_AC_9_CFG_BRIDGE_DST_BUSECC_ENABLE_CLR — Interrupt Enable Clear Register for Ij7am_ac_cfg_cbass_0_j7am_ac_cfg_cbass_Ij7am_main_ac_ecc_aggr_main_ac_9_cfg_p2p_bridge_Ij7am_main_ac_ecc_aggr_main_ac_9_cfg_bridge_dst_busecc_pend (access R/W1TC)
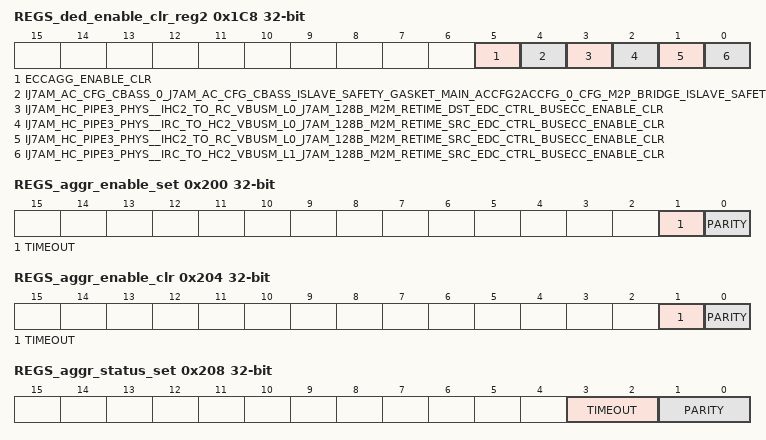
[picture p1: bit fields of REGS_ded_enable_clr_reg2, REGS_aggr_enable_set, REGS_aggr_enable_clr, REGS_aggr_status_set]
0x1C8 REGS_ded_enable_clr_reg2 — Interrupt Enable Clear Register 2
  [5] ECCAGG_ENABLE_CLR — Interrupt Enable Clear Register for eccagg_pend (access R/W1TC)
  [4] IJ7AM_AC_CFG_CBASS_0_J7AM_AC_CFG_CBASS_ISLAVE_SAFETY_GASKET_MAIN_ACCFG2ACCFG_0_CFG_M2P_BRIDGE_ISLAVE_SAFETY_GASKET_MAIN_ACCFG2ACCFG_0_CFG_BRIDGE_BUSECC_ENABLE_CLR — Interrupt Enable Clear Register for Ij7am_ac_cfg_cbass_0_j7am_ac_cfg_cbass_Islave_safety_gasket_main_accfg2accfg_0_cfg_m2p_bridge_Islave_safety_gasket_main_accfg2accfg_0_cfg_bridge_busecc_pend (access R/W1TC)
  [3] IJ7AM_HC_PIPE3_PHYS__IHC2_TO_RC_VBUSM_L0_J7AM_128B_M2M_RETIME_DST_EDC_CTRL_BUSECC_ENABLE_CLR — Interrupt Enable Clear Register for Ij7am_hc_pipe3_phys__Ihc2_to_rc_vbusm_l0_j7am_128b_m2m_retime_dst_edc_ctrl_busecc_pend (access R/W1TC)
  [2] IJ7AM_HC_PIPE3_PHYS__IRC_TO_HC2_VBUSM_L0_J7AM_128B_M2M_RETIME_SRC_EDC_CTRL_BUSECC_ENABLE_CLR — Interrupt Enable Clear Register for Ij7am_hc_pipe3_phys__Irc_to_hc2_vbusm_l0_j7am_128b_m2m_retime_src_edc_ctrl_busecc_pend (access R/W1TC)
  [1] IJ7AM_HC_PIPE3_PHYS__IHC2_TO_RC_VBUSM_L0_J7AM_128B_M2M_RETIME_SRC_EDC_CTRL_BUSECC_ENABLE_CLR — Interrupt Enable Clear Register for Ij7am_hc_pipe3_phys__Ihc2_to_rc_vbusm_l0_j7am_128b_m2m_retime_src_edc_ctrl_busecc_pend (access R/W1TC)
  [0] IJ7AM_HC_PIPE3_PHYS__IRC_TO_HC2_VBUSM_L1_J7AM_128B_M2M_RETIME_SRC_EDC_CTRL_BUSECC_ENABLE_CLR — Interrupt Enable Clear Register for Ij7am_hc_pipe3_phys__Irc_to_hc2_vbusm_l1_j7am_128b_m2m_retime_src_edc_ctrl_busecc_pend (access R/W1TC)
0x200 REGS_aggr_enable_set — AGGR interrupt enable set Register
  [1] TIMEOUT — interrupt enable set for svbus timeout errors (access R/W1TS)
  [0] PARITY — interrupt enable set for parity errors (access R/W1TS)
0x204 REGS_aggr_enable_clr — AGGR interrupt enable clear Register
  [1] TIMEOUT — interrupt enable clear for svbus timeout errors (access R/W1TC)
  [0] PARITY — interrupt enable clear for parity errors (access R/W1TC)
0x208 REGS_aggr_status_set — AGGR interrupt status set Register
  [3:2] TIMEOUT — interrupt status set for svbus timeout errors (access R/WI)
  [1:0] PARITY — interrupt status set for parity errors (access R/WI)
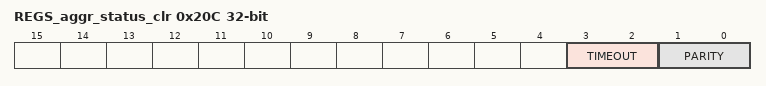
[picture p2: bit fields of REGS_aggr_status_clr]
0x20C REGS_aggr_status_clr — AGGR interrupt status clear Register
  [3:2] TIMEOUT — interrupt status clear for svbus timeout errors (access R/WD)
  [1:0] PARITY — interrupt status clear for parity errors (access R/WD)
